# HC32F467 register map
File version: 1.0
CPU: CM4 r0p1, little endian, MPU, FPU, 4 interrupt priority bits
Registers are 32-bit, read-write, reset 0x0 unless marked. A register's access mark holds for its fields unless they carry their own. Offsets are from the block's base; [hi:lo] are bit positions; {n}, {i} and the like mark numbered series.

## OTS
Base 0x40010600
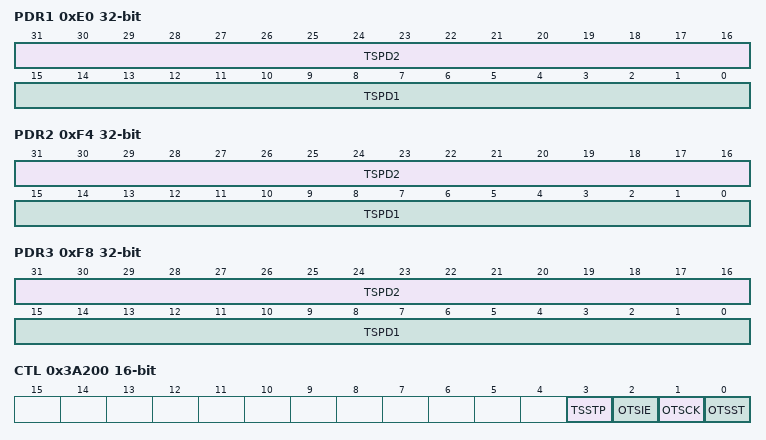
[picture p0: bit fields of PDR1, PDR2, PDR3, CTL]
0xE0 PDR1
  [31:16] TSPD2, [15:0] TSPD1
0xF4 PDR2
  [31:16] TSPD2, [15:0] TSPD1
0xF8 PDR3
  [31:16] TSPD2, [15:0] TSPD1
0x3A200 CTL 16-bit
  [3] TSSTP, [2] OTSIE, [1] OTSCK, [0] OTSST
0x3A202 DR1 16-bit
0x3A204 DR2 16-bit
0x3A206 ECR 16-bit

## PERIC
Base 0x40055400
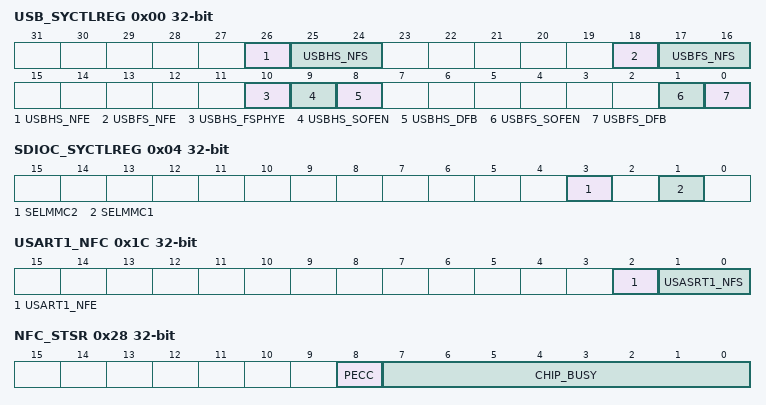
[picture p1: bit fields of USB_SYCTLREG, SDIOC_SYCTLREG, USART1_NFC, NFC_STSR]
0x00 USB_SYCTLREG
  [26] USBHS_NFE, [25:24] USBHS_NFS, [18] USBFS_NFE, [17:16] USBFS_NFS, [10] USBHS_FSPHYE, [9] USBHS_SOFEN, [8] USBHS_DFB, [1] USBFS_SOFEN, [0] USBFS_DFB
0x04 SDIOC_SYCTLREG
  [3] SELMMC2, [1] SELMMC1
0x08 NFC_STCR
  [0] OPENP
0x0C NFC_ENAR
  [2] NFCEN
0x0C SMC_ENAR (alternate view of NFC_ENAR)
  [1] SMCEN
0x0C DMC_ENAR (alternate view of NFC_ENAR)
  [0] DMCEN
0x1C USART1_NFC
  [2] USART1_NFE, [1:0] USASRT1_NFS
0x28 NFC_STSR ro
  [8] PECC, [7:0] CHIP_BUSY

## PWC
Base 0x40048000
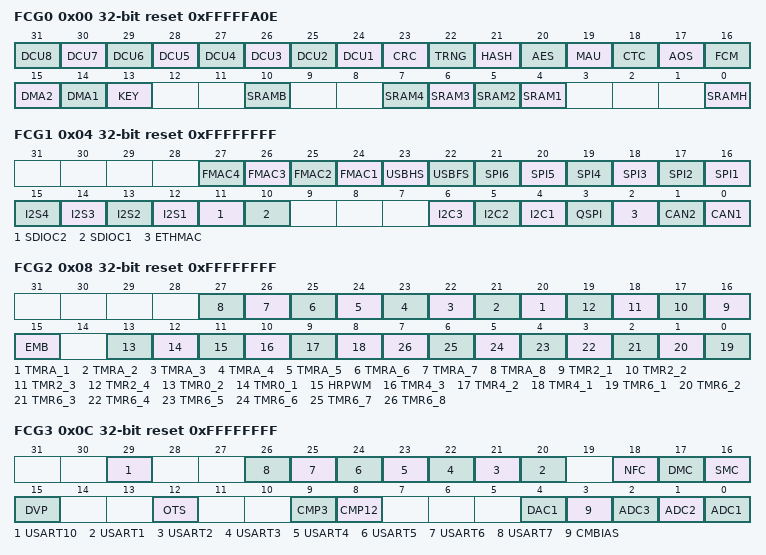
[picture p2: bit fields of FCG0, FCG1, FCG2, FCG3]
0x00 FCG0 reset 0xFFFFFA0E
  [n+23] DCU{n} (n=1..8), [23] CRC, [22] TRNG, [21] HASH, [20] AES, [19] MAU, [18] CTC, [17] AOS, [16] FCM, [15] DMA2, [14] DMA1, [13] KEY, [10] SRAMB, [n+3] SRAM{n} (n=1..4), [0] SRAMH
0x04 FCG1 reset 0xFFFFFFFF
  [n+23] FMAC{n} (n=1..4), [23] USBHS, [22] USBFS, [n+15] SPI{n} (n=1..6), [n+11] I2S{n} (n=1..4), [11] SDIOC2, [10] SDIOC1, [6] I2C3, [5] I2C2, [4] I2C1, [3] QSPI, [2] ETHMAC, [1] CAN2, [0] CAN1
0x08 FCG2 reset 0xFFFFFFFF
  [n+19] TMRA_{n} (n=1..8), [n+15] TMR2_{n} (n=1..4), [15] EMB, [13] TMR0_2, [12] TMR0_1, [11] HRPWM, [10] TMR4_3, [9] TMR4_2, [8] TMR4_1, [n-1] TMR6_{n} (n=1..8)
0x0C FCG3 reset 0xFFFFFFFF
  [29] USART10, [n+19] USART{n} (n=1..7), [18] NFC, [17] DMC, [16] SMC, [15] DVP, [12] OTS, [9] CMP3, [8] CMP12, [4] DAC1, [3] CMBIAS, [2] ADC3, [1] ADC2, [0] ADC1
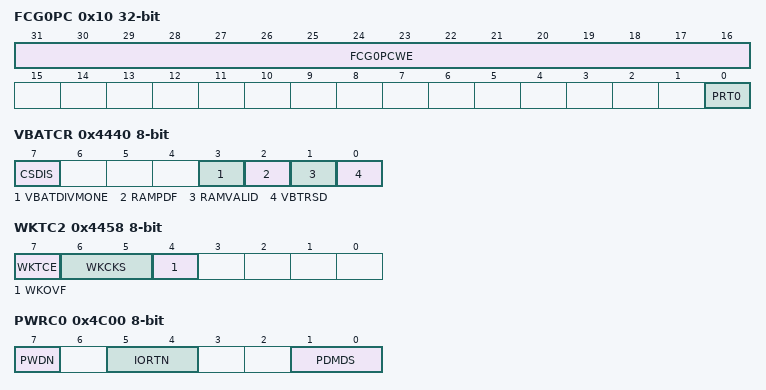
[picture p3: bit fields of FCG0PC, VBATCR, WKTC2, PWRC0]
0x10 FCG0PC
  [31:16] FCG0PCWE wo, [0] PRT0
0x4430 VBATRSTR 8-bit
0x4440 VBATCR 8-bit
  [7] CSDIS, [3] VBATDIVMONE, [2] RAMPDF, [1] RAMVALID, [0] VBTRSD
0x4450 WKTC0 8-bit
  [7:0] WKTMCMP
0x4454 WKTC1 8-bit
  [3:0] WKTMCMP
0x4458 WKTC2 8-bit
  [7] WKTCE, [6:5] WKCKS, [4] WKOVF
{0x4600+4i} BKR{i} 8-bit (i=0..127)
0x4C00 PWRC0 8-bit
  [7] PWDN, [5:4] IORTN, [1:0] PDMDS
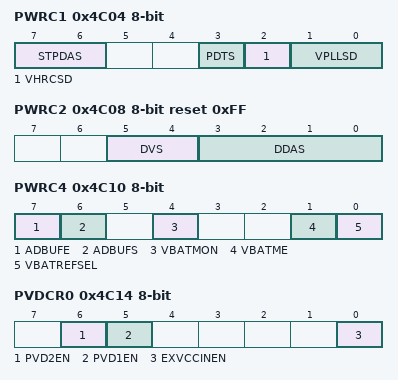
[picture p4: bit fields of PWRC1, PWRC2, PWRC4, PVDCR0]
0x4C04 PWRC1 8-bit
  [7:6] STPDAS, [3] PDTS, [2] VHRCSD, [1:0] VPLLSD
0x4C08 PWRC2 8-bit reset 0xFF
  [5:4] DVS, [3:0] DDAS
0x4C0C PWRC3 8-bit reset 0xFF
  [7:0] DDAS
0x4C10 PWRC4 8-bit
  [7] ADBUFE, [6] ADBUFS, [4] VBATMON, [1] VBATME, [0] VBATREFSEL
0x4C14 PVDCR0 8-bit
  [6] PVD2EN, [5] PVD1EN, [0] EXVCCINEN
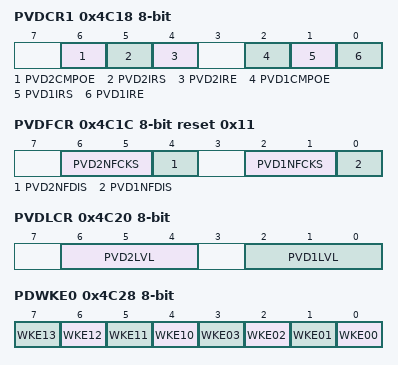
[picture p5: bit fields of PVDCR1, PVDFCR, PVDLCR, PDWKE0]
0x4C18 PVDCR1 8-bit
  [6] PVD2CMPOE, [5] PVD2IRS, [4] PVD2IRE, [2] PVD1CMPOE, [1] PVD1IRS, [0] PVD1IRE
0x4C1C PVDFCR 8-bit reset 0x11
  [6:5] PVD2NFCKS, [4] PVD2NFDIS, [2:1] PVD1NFCKS, [0] PVD1NFDIS
0x4C20 PVDLCR 8-bit
  [6:4] PVD2LVL, [2:0] PVD1LVL
0x4C28 PDWKE0 8-bit
  [n-6] WKE{n} (n=10..13), [n] WKE{n:02} (n=0..3)
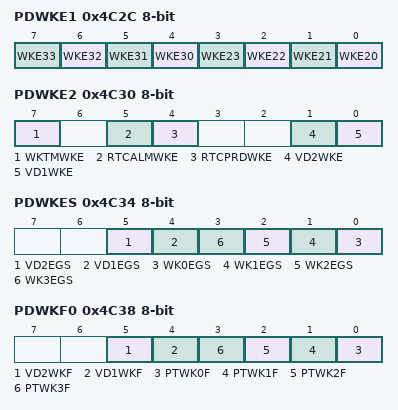
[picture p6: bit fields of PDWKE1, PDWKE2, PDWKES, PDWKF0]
0x4C2C PDWKE1 8-bit
  [n-26] WKE{n} (n=30..33), [n-20] WKE{n} (n=20..23)
0x4C30 PDWKE2 8-bit
  [7] WKTMWKE, [5] RTCALMWKE, [4] RTCPRDWKE, [1] VD2WKE, [0] VD1WKE
0x4C34 PDWKES 8-bit
  [5] VD2EGS, [4] VD1EGS, [n] WK{n}EGS (n=0..3)
0x4C38 PDWKF0 8-bit
  [5] VD2WKF, [4] VD1WKF, [n] PTWK{n}F (n=0..3)
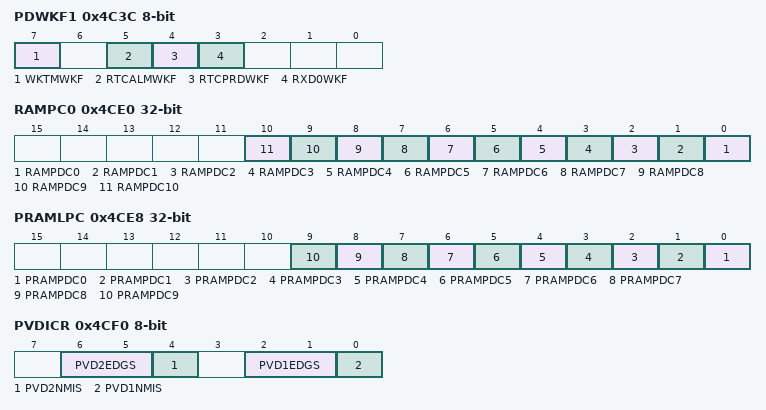
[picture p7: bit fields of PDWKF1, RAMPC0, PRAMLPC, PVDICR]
0x4C3C PDWKF1 8-bit
  [7] WKTMWKF, [5] RTCALMWKF, [4] RTCPRDWKF, [3] RXD0WKF
0x4CE0 RAMPC0
  [n] RAMPDC{n} (n=0..10)
0x4CE4 RAMOPM 16-bit reset 0x8043
0x4CE8 PRAMLPC
  [n] PRAMPDC{n} (n=0..9)
0x4CF0 PVDICR 8-bit
  [6:5] PVD2EDGS, [4] PVD2NMIS, [2:1] PVD1EDGS, [0] PVD1NMIS
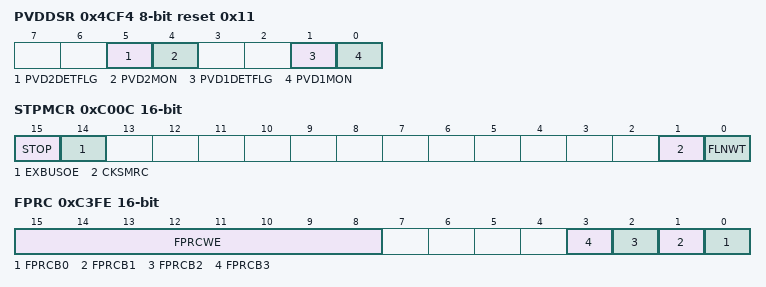
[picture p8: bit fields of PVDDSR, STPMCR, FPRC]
0x4CF4 PVDDSR 8-bit reset 0x11
  [5] PVD2DETFLG, [4] PVD2MON, [1] PVD1DETFLG, [0] PVD1MON
0xC00C STPMCR 16-bit
  [15] STOP, [14] EXBUSOE, [1] CKSMRC, [0] FLNWT
0xC3FE FPRC 16-bit
  [15:8] FPRCWE, [n] FPRCB{n} (n=0..3)

## QSPI
Base 0x9C000000
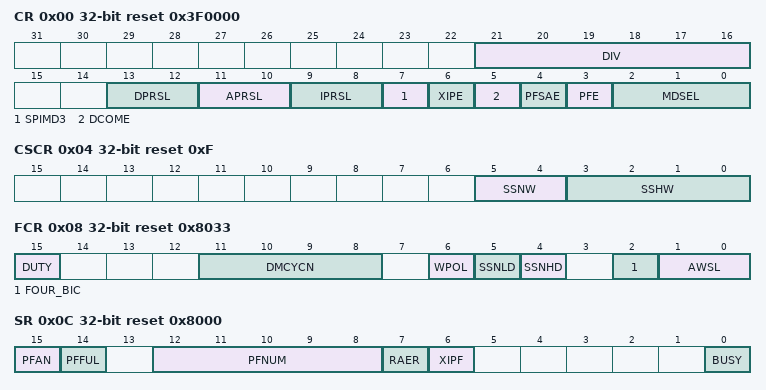
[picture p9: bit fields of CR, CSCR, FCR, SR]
0x00 CR reset 0x3F0000
  [21:16] DIV, [13:12] DPRSL, [11:10] APRSL, [9:8] IPRSL, [7] SPIMD3, [6] XIPE, [5] DCOME, [4] PFSAE, [3] PFE, [2:0] MDSEL
0x04 CSCR reset 0xF
  [5:4] SSNW, [3:0] SSHW
0x08 FCR reset 0x8033
  [15] DUTY, [11:8] DMCYCN, [6] WPOL, [5] SSNLD, [4] SSNHD, [2] FOUR_BIC, [1:0] AWSL
0x0C SR reset 0x8000
  [15] PFAN, [14] PFFUL, [12:8] PFNUM, [7] RAER, [6] XIPF, [0] BUSY
0x10 DCOM
  [7:0] DCOM
0x14 CCMD
  [7:0] RIC
0x18 XCMD reset 0xFF
  [7:0] XIPMC
0x24 CLR wo
  [7] RAERCLR
0x804 EXAR
  [31:26] EXADR
